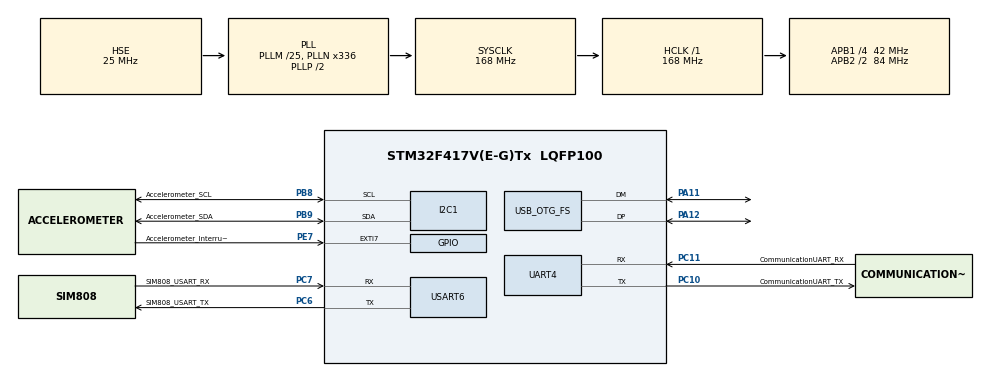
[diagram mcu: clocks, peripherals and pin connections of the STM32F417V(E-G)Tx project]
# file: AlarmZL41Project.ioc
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I2C1.DutyCycle=I2C_DUTYCYCLE_2
I2C1.I2C_Mode=I2C_Fast
Mcu.Family=STM32F4
Mcu.Name=STM32F417V(E-G)Tx
Mcu.Package=LQFP100
Mcu.UserConstants=TIM6_PRESCALER,8399;TIM6_COUNTER,999;TIM7_PRESCALER,8399;TIM7_COUNTER,9999
NVIC.EXTI9_5_IRQn=true\:0\:0\:false\:false\:true
NVIC.OTG_FS_IRQn=true\:0\:0\:false\:false\:true
NVIC.PriorityGroup=NVIC_PRIORITYGROUP_4
NVIC.TIM6_DAC_IRQn=true\:0\:0\:false\:false\:true
NVIC.TIM7_IRQn=true\:0\:0\:false\:false\:true
NVIC.UART4_IRQn=true\:0\:0\:false\:false\:true
NVIC.USART6_IRQn=true\:0\:0\:false\:false\:true
PA11.Mode=Device_Only
PA11.Signal=USB_OTG_FS_DM
PA12.Mode=Device_Only
PA12.Signal=USB_OTG_FS_DP
PA13.Mode=Serial_Wire
PA13.Signal=SYS_JTMS-SWDIO
PA14.Mode=Serial_Wire
PA14.Signal=SYS_JTCK-SWCLK
PB8.GPIO_Label=Accelerometer_SCL
PB8.Mode=I2C
PB8.Signal=I2C1_SCL
PB9.GPIO_Label=Accelerometer_SDA
PB9.Mode=I2C
PB9.Signal=I2C1_SDA
PC10.GPIO_Label=CommunicationUART_TX
PC10.Mode=Asynchronous
PC10.Signal=UART4_TX
PC11.GPIO_Label=CommunicationUART_RX
PC11.Mode=Asynchronous
PC11.Signal=UART4_RX
PC6.GPIO_Label=SIM808_USART_TX
PC6.Mode=Asynchronous
PC6.Signal=USART6_TX
PC7.GPIO_Label=SIM808_USART_RX
PC7.Mode=Asynchronous
PC7.Signal=USART6_RX
PE7.GPIO_Label=Accelerometer_Interrupt
PE7.Signal=GPXTI7
PH0-OSC_IN.Mode=HSE-External-Oscillator
PH0-OSC_IN.Signal=RCC_OSC_IN
PH1-OSC_OUT.Mode=HSE-External-Oscillator
PH1-OSC_OUT.Signal=RCC_OSC_OUT
ProjectManager.HeapSize=0x200
ProjectManager.StackSize=0x400
ProjectManager.TargetToolchain=TrueSTUDIO
RCC.48MHZClocksFreq_Value=48000000
RCC.AHBCLKDivider=RCC_SYSCLK_DIV1
RCC.AHBFreq_Value=168000000
RCC.APB1CLKDivider=RCC_HCLK_DIV4
RCC.APB1Freq_Value=42000000
RCC.APB1TimFreq_Value=84000000
RCC.APB2CLKDivider=RCC_HCLK_DIV2
RCC.APB2Freq_Value=84000000
RCC.APB2TimFreq_Value=168000000
RCC.ClockTypeHCLK=RCC_CLOCKTYPE_HCLK
RCC.ClockTypePCLK1=RCC_CLOCKTYPE_PCLK1
RCC.ClockTypePCLK2=RCC_CLOCKTYPE_PCLK2
RCC.ClockTypeSysClk=RCC_CLOCKTYPE_SYSCLK
RCC.CortexFreq_Value=168000000
RCC.Cortex_Div=SYSTICK_CLKSOURCE_HCLK
RCC.EnableExtClockForI2S=false
RCC.EnableHSE=true
RCC.EnableHSERTCDevisor=true
RCC.EnableLSE=false
RCC.EnableLSERTC=false
RCC.ExtClockEnable=false
RCC.HCLKFreq_Value=168000000
RCC.HSEState=RCC_HSE_ON
RCC.HSE_VALUE=25000000
RCC.HSIState=RCC_HSI_OFF
RCC.HSI_VALUE=16000000
RCC.I2SEnable=false
RCC.IWDGEnable=false
RCC.LSE_VALUE=32768
RCC.LSIState=RCC_LSI_ON
RCC.MCO1OutPutEnable=false
RCC.MCO2OutPutEnable=false
RCC.OscillatorTypeHSE=RCC_OSCILLATORTYPE_HSE
RCC.OscillatorTypeHSI=RCC_OSCILLATORTYPE_HSI
RCC.OscillatorTypeLSI=RCC_OSCILLATORTYPE_LSI
RCC.PLLM=25
RCC.PLLN=336
RCC.PLLP=RCC_PLLP_DIV2
RCC.PLLQ=7
RCC.PLLSource=RCC_PLLSOURCE_HSE
RCC.PLLSourceVirtual=RCC_PLLSOURCE_HSE
RCC.PLLState=RCC_PLL_ON
RCC.RCC_MCODiv1=RCC_MCODIV_1
RCC.RCC_MCODiv2=RCC_MCODIV_1
RCC.RCC_PERIPHCLK_RTCVar=RCC_PERIPHCLK_RTC
RCC.RCC_RTC_Clock_Source_FROM_HSE=RCC_RTCCLKSOURCE_HSE_DIV2
RCC.RNGEnable=false
RCC.RTCEnable=true
RCC.SDIOEnable=false
RCC.SYSCLKFreq_VALUE=168000000
RCC.SYSCLKSource=RCC_SYSCLKSOURCE_PLLCLK
RCC.USBFSEnable=true
RCC.USBHSEnable=false
RCC.VCOOutputFreq_Value=336000000
RTC.OutPut=RTC_OUTPUT_DISABLE
RTC.OutPutPolarity=RTC_OUTPUT_POLARITY_HIGH
RTC.OutPutType=RTC_OUTPUT_TYPE_OPENDRAIN
TIM6.Period=TIM6_COUNTER
TIM6.Prescaler=TIM6_PRESCALER
TIM6.TIM_MasterSlaveMode=TIM_MASTERSLAVEMODE_DISABLE
TIM7.Period=TIM7_COUNTER
TIM7.Prescaler=TIM7_PRESCALER
TIM7.TIM_MasterSlaveMode=TIM_MASTERSLAVEMODE_DISABLE
UART4.VirtualMode=Asynchronous
USART6.HwFlowCtl=UART_HWCONTROL_NONE
USART6.VirtualMode=VM_ASYNC
USB_DEVICE.CLASS_NAME_FS=CDC
USB_DEVICE.USBD_HandleTypeDef_FS=hUsbDevice_OTG_FS
USB_DEVICE.VirtualModeFS=Cdc_FS
USB_OTG_FS.VirtualMode=Device_Only
USB_OTG_FS.dev_endpoints=4
USB_OTG_FS.phy_itface=PCD_PHY_EMBEDDED
VP_RTC_VS_RTC_Activate.Mode=RTC_Enabled
VP_RTC_VS_RTC_Calendar.Mode=RTC_Calendar
VP_TIM6_VS_ClockSourceINT.Mode=Enable_Timer
VP_TIM7_VS_ClockSourceINT.Mode=Enable_Timer
VP_USB_DEVICE_VS_USB_DEVICE_CDC_FS.Mode=CDC_FS
board=AlarmZL41Project

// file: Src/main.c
/**
  ******************************************************************************
  * File Name          : main.c
  * Description        : Main program body
  ******************************************************************************
  *
  * Copyright (c) 2017 STMicroelectronics International N.V.
  * All rights reserved.
  *
  * Redistribution and use in source and binary forms, with or without
  * modification, are permitted, provided that the following conditions are met:
  *
  * 1. Redistribution of source code must retain the above copyright notice,
  *    this list of conditions and the following disclaimer.
  * 2. Redistributions in binary form must reproduce the above copyright notice,
  *    this list of conditions and the following disclaimer in the documentation
  *    and/or other materials provided with the distribution.
  * 3. Neither the name of STMicroelectronics nor the names of other
  *    contributors to this software may be used to endorse or promote products
  *    derived from this software without specific written permission.
  * 4. This software, including modifications and/or derivative works of this
  *    software, must execute solely and exclusively on microcontroller or
  *    microprocessor devices manufactured by or for STMicroelectronics.
  * 5. Redistribution and use of this software other than as permitted under
  *    this license is void and will automatically terminate your rights under
  *    this license.
  *
  * THIS SOFTWARE IS PROVIDED BY STMICROELECTRONICS AND CONTRIBUTORS "AS IS"
  * AND ANY EXPRESS, IMPLIED OR STATUTORY WARRANTIES, INCLUDING, BUT NOT
  * LIMITED TO, THE IMPLIED WARRANTIES OF MERCHANTABILITY, FITNESS FOR A
  * PARTICULAR PURPOSE AND NON-INFRINGEMENT OF THIRD PARTY INTELLECTUAL PROPERTY
  * RIGHTS ARE DISCLAIMED TO THE FULLEST EXTENT PERMITTED BY LAW. IN NO EVENT
  * SHALL STMICROELECTRONICS OR CONTRIBUTORS BE LIABLE FOR ANY DIRECT, INDIRECT,
  * INCIDENTAL, SPECIAL, EXEMPLARY, OR CONSEQUENTIAL DAMAGES (INCLUDING, BUT NOT
  * LIMITED TO, PROCUREMENT OF SUBSTITUTE GOODS OR SERVICES; LOSS OF USE, DATA,
  * OR PROFITS; OR BUSINESS INTERRUPTION) HOWEVER CAUSED AND ON ANY THEORY OF
  * LIABILITY, WHETHER IN CONTRACT, STRICT LIABILITY, OR TORT (INCLUDING
  * NEGLIGENCE OR OTHERWISE) ARISING IN ANY WAY OUT OF THE USE OF THIS SOFTWARE,
  * EVEN IF ADVISED OF THE POSSIBILITY OF SUCH DAMAGE.
  *
  ******************************************************************************
  */
#include "main.h"
#include "stm32f4xx_hal.h"
#include "i2c.h"
#include "rtc.h"
#include "tim.h"
#include "usart.h"
#include "usb_device.h"
#include "gpio.h"

/* USER CODE BEGIN Includes */
#include "usbd_cdc_if.h"
#include "Accelerometer.h"
#include "EEPROM.h"
#include "PositionLog.h"
#include "USBTransmission.h"
#include "GSM.h"
#include "GPS.h"
/* USER CODE END Includes */

/* USER CODE BEGIN PV */
/* Private variables ---------------------------------------------------------*/

/* USER CODE END PV */

void SystemClock_Config(void);
void Error_Handler(void);

/* USER CODE BEGIN PFP */
/* Private function prototypes -----------------------------------------------*/

/* USER CODE END PFP */

/* USER CODE BEGIN 0 */
uint8_t rcvData[1];
HAL_StatusTypeDef status=HAL_BUSY;
/* USER CODE END 0 */

int main(void)
{

  /* MCU Configuration----------------------------------------------------------*/

  /* Reset of all peripherals, Initializes the Flash interface and the Systick. */
  HAL_Init();

  /* Configure the system clock */
  SystemClock_Config();

  /* Initialize all configured peripherals */
  MX_GPIO_Init();
  MX_USB_DEVICE_Init();
  MX_I2C1_Init();
  MX_UART4_Init();
  MX_USART6_UART_Init();
  MX_TIM6_Init();
  MX_RTC_Init();
  MX_TIM7_Init();

  /* USER CODE BEGIN 2 */
  status=HAL_I2C_Mem_Read(&hi2c1,0x68,0x3B,1,rcvData,1,1000);

  AccelerometerInit();
  //GSM_Init();
  /* USER CODE END 2 */

  /* Infinite loop */
  while (1)
  {

  }

}

/** System Clock Configuration
*/
void SystemClock_Config(void)
{

  RCC_OscInitTypeDef RCC_OscInitStruct;
  RCC_ClkInitTypeDef RCC_ClkInitStruct;
  RCC_PeriphCLKInitTypeDef PeriphClkInitStruct;

    /**Configure the main internal regulator output voltage
    */
  __HAL_RCC_PWR_CLK_ENABLE();

  __HAL_PWR_VOLTAGESCALING_CONFIG(PWR_REGULATOR_VOLTAGE_SCALE1);

    /**Initializes the CPU, AHB and APB busses clocks
    */
  RCC_OscInitStruct.OscillatorType = RCC_OSCILLATORTYPE_HSI|RCC_OSCILLATORTYPE_LSI
                              |RCC_OSCILLATORTYPE_HSE;
  RCC_OscInitStruct.HSEState = RCC_HSE_ON;
  RCC_OscInitStruct.LSIState = RCC_LSI_ON;
  RCC_OscInitStruct.PLL.PLLState = RCC_PLL_ON;
  RCC_OscInitStruct.PLL.PLLSource = RCC_PLLSOURCE_HSE;
  RCC_OscInitStruct.PLL.PLLM = 25;
  RCC_OscInitStruct.PLL.PLLN = 336;
  RCC_OscInitStruct.PLL.PLLP = RCC_PLLP_DIV2;
  RCC_OscInitStruct.PLL.PLLQ = 7;
  if (HAL_RCC_OscConfig(&RCC_OscInitStruct) != HAL_OK)
  {
    Error_Handler();
  }

    /**Initializes the CPU, AHB and APB busses clocks
    */
  RCC_ClkInitStruct.ClockType = RCC_CLOCKTYPE_HCLK|RCC_CLOCKTYPE_SYSCLK
                              |RCC_CLOCKTYPE_PCLK1|RCC_CLOCKTYPE_PCLK2;
  RCC_ClkInitStruct.SYSCLKSource = RCC_SYSCLKSOURCE_PLLCLK;
  RCC_ClkInitStruct.AHBCLKDivider = RCC_SYSCLK_DIV1;
  RCC_ClkInitStruct.APB1CLKDivider = RCC_HCLK_DIV4;
  RCC_ClkInitStruct.APB2CLKDivider = RCC_HCLK_DIV2;

  if (HAL_RCC_ClockConfig(&RCC_ClkInitStruct, FLASH_LATENCY_5) != HAL_OK)
  {
    Error_Handler();
  }

  PeriphClkInitStruct.PeriphClockSelection = RCC_PERIPHCLK_RTC;
  PeriphClkInitStruct.RTCClockSelection = RCC_RTCCLKSOURCE_LSI;
  if (HAL_RCCEx_PeriphCLKConfig(&PeriphClkInitStruct) != HAL_OK)
  {
    Error_Handler();
  }

    /**Configure the Systick interrupt time
    */
  HAL_SYSTICK_Config(HAL_RCC_GetHCLKFreq()/1000);

    /**Configure the Systick
    */
  HAL_SYSTICK_CLKSourceConfig(SYSTICK_CLKSOURCE_HCLK);

  /* SysTick_IRQn interrupt configuration */
  HAL_NVIC_SetPriority(SysTick_IRQn, 0, 0);
}

void Error_Handler(void)
{
  /* USER CODE BEGIN Error_Handler */
  /* User can add his own implementation to report the HAL error return state */
  /*while(1)
  {
  }*/
  /* USER CODE END Error_Handler */
}

/************************ (C) COPYRIGHT STMicroelectronics *****END OF FILE****/
